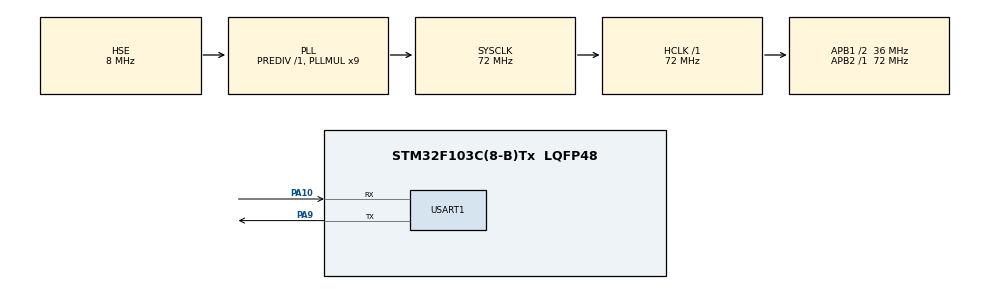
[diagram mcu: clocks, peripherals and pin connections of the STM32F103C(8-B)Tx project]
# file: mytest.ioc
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Dma.Request0=USART1_RX
Dma.Request1=USART1_TX
Dma.USART1_RX.0.Direction=DMA_PERIPH_TO_MEMORY
Dma.USART1_RX.0.Instance=DMA1_Channel5
Dma.USART1_RX.0.MemDataAlignment=DMA_MDATAALIGN_BYTE
Dma.USART1_RX.0.MemInc=DMA_MINC_ENABLE
Dma.USART1_RX.0.Mode=DMA_NORMAL
Dma.USART1_RX.0.PeriphDataAlignment=DMA_PDATAALIGN_BYTE
Dma.USART1_RX.0.PeriphInc=DMA_PINC_DISABLE
Dma.USART1_RX.0.Priority=DMA_PRIORITY_VERY_HIGH
Dma.USART1_TX.1.Direction=DMA_MEMORY_TO_PERIPH
Dma.USART1_TX.1.Instance=DMA1_Channel4
Dma.USART1_TX.1.MemDataAlignment=DMA_MDATAALIGN_BYTE
Dma.USART1_TX.1.MemInc=DMA_MINC_ENABLE
Dma.USART1_TX.1.Mode=DMA_NORMAL
Dma.USART1_TX.1.PeriphDataAlignment=DMA_PDATAALIGN_BYTE
Dma.USART1_TX.1.PeriphInc=DMA_PINC_DISABLE
Dma.USART1_TX.1.Priority=DMA_PRIORITY_VERY_HIGH
FREERTOS.Queues01=rxQueue,5,void *,0,Dynamic,NULL,NULL
FREERTOS.Tasks01=defaultTask,-2,128,StartDefaultTask,Default,NULL,Dynamic,NULL,NULL;main_task,0,128,StartTask02,Default,NULL,Dynamic,NULL,NULL;uartRx_task,2,256,uart_rx_entry,Default,NULL,Dynamic,NULL,NULL
FREERTOS.configTOTAL_HEAP_SIZE=4096
Mcu.Family=STM32F1
Mcu.Name=STM32F103C(8-B)Tx
Mcu.Package=LQFP48
NVIC.DMA1_Channel4_IRQn=true\:5\:0\:false\:false\:true\:true\:false\:true\:true
NVIC.DMA1_Channel5_IRQn=true\:5\:0\:true\:false\:true\:true\:false\:true\:true
NVIC.PriorityGroup=NVIC_PRIORITYGROUP_4
NVIC.TIM1_UP_IRQn=true\:0\:0\:false\:false\:true\:false\:false\:true\:true
NVIC.TimeBase=TIM1_UP_IRQn
NVIC.TimeBaseIP=TIM1
NVIC.USART1_IRQn=true\:5\:0\:true\:false\:true\:true\:true\:true\:true
PA10.Mode=Asynchronous
PA10.Signal=USART1_RX
PA13.Mode=Serial_Wire
PA13.Signal=SYS_JTMS-SWDIO
PA14.Mode=Serial_Wire
PA14.Signal=SYS_JTCK-SWCLK
PA9.Mode=Asynchronous
PA9.Signal=USART1_TX
PD0-OSC_IN.Mode=HSE-External-Oscillator
PD0-OSC_IN.Signal=RCC_OSC_IN
PD1-OSC_OUT.Mode=HSE-External-Oscillator
PD1-OSC_OUT.Signal=RCC_OSC_OUT
ProjectManager.HeapSize=0x200
ProjectManager.StackSize=0x400
ProjectManager.TargetToolchain=MDK-ARM V5.32
RCC.AHBFreq_Value=72000000
RCC.APB1CLKDivider=RCC_HCLK_DIV2
RCC.APB1Freq_Value=36000000
RCC.APB1TimFreq_Value=72000000
RCC.APB2Freq_Value=72000000
RCC.APB2TimFreq_Value=72000000
RCC.HCLKFreq_Value=72000000
RCC.PLLMUL=RCC_PLL_MUL9
RCC.PLLSourceVirtual=RCC_PLLSOURCE_HSE
RCC.SYSCLKFreq_VALUE=72000000
RCC.SYSCLKSource=RCC_SYSCLKSOURCE_PLLCLK
RCC.USBFreq_Value=72000000
USART1.VirtualMode=VM_ASYNC
VP_FREERTOS_VS_CMSIS_V1.Mode=CMSIS_V1
VP_SYS_VS_tim1.Mode=TIM1
board=custom

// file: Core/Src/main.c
/* USER CODE BEGIN Header */
/**
  ******************************************************************************
  * @file           : main.c
  * @brief          : Main program body
  ******************************************************************************
  * @attention
  *
  * Copyright (c) 2025 STMicroelectronics.
  * All rights reserved.
  *
  * This software is licensed under terms that can be found in the LICENSE file
  * in the root directory of this software component.
  * If no LICENSE file comes with this software, it is provided AS-IS.
  *
  ******************************************************************************
  */
/* USER CODE END Header */
#include "main.h"
#include "cmsis_os.h"
#include "dma.h"
#include "usart.h"
#include "gpio.h"

void SystemClock_Config(void);
void MX_FREERTOS_Init(void);

int main(void)
{

  /* MCU Configuration--------------------------------------------------------*/

  /* Reset of all peripherals, Initializes the Flash interface and the Systick. */
  HAL_Init();

  /* Configure the system clock */
  SystemClock_Config();

  /* Initialize all configured peripherals */
  MX_GPIO_Init();
  MX_DMA_Init();
  MX_USART1_UART_Init();

  /* Call init function for freertos objects (in freertos.c) */
  MX_FREERTOS_Init();

  /* Start scheduler */
  osKernelStart();

  /* We should never get here as control is now taken by the scheduler */
  /* Infinite loop */
  while (1)
  {

  }
}

void SystemClock_Config(void)
{
  RCC_OscInitTypeDef RCC_OscInitStruct = {0};
  RCC_ClkInitTypeDef RCC_ClkInitStruct = {0};

  /** Initializes the RCC Oscillators according to the specified parameters
  * in the RCC_OscInitTypeDef structure.
  */
  RCC_OscInitStruct.OscillatorType = RCC_OSCILLATORTYPE_HSE;
  RCC_OscInitStruct.HSEState = RCC_HSE_ON;
  RCC_OscInitStruct.HSEPredivValue = RCC_HSE_PREDIV_DIV1;
  RCC_OscInitStruct.HSIState = RCC_HSI_ON;
  RCC_OscInitStruct.PLL.PLLState = RCC_PLL_ON;
  RCC_OscInitStruct.PLL.PLLSource = RCC_PLLSOURCE_HSE;
  RCC_OscInitStruct.PLL.PLLMUL = RCC_PLL_MUL9;
  if (HAL_RCC_OscConfig(&RCC_OscInitStruct) != HAL_OK)
  {
    Error_Handler();
  }

  /** Initializes the CPU, AHB and APB buses clocks
  */
  RCC_ClkInitStruct.ClockType = RCC_CLOCKTYPE_HCLK|RCC_CLOCKTYPE_SYSCLK
                              |RCC_CLOCKTYPE_PCLK1|RCC_CLOCKTYPE_PCLK2;
  RCC_ClkInitStruct.SYSCLKSource = RCC_SYSCLKSOURCE_PLLCLK;
  RCC_ClkInitStruct.AHBCLKDivider = RCC_SYSCLK_DIV1;
  RCC_ClkInitStruct.APB1CLKDivider = RCC_HCLK_DIV2;
  RCC_ClkInitStruct.APB2CLKDivider = RCC_HCLK_DIV1;

  if (HAL_RCC_ClockConfig(&RCC_ClkInitStruct, FLASH_LATENCY_2) != HAL_OK)
  {
    Error_Handler();
  }
}

void HAL_TIM_PeriodElapsedCallback(TIM_HandleTypeDef *htim)
{
  if (htim->Instance == TIM1) {
    HAL_IncTick();
  }
}

void Error_Handler(void)
{
  __disable_irq();
  while (1)
  {
  }
}

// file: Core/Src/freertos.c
/* USER CODE BEGIN Header */
/**
  ******************************************************************************
  * File Name          : freertos.c
  * Description        : Code for freertos applications
  ******************************************************************************
  * @attention
  *
  * Copyright (c) 2025 STMicroelectronics.
  * All rights reserved.
  *
  * This software is licensed under terms that can be found in the LICENSE file
  * in the root directory of this software component.
  * If no LICENSE file comes with this software, it is provided AS-IS.
  *
  ******************************************************************************
  */
/* USER CODE END Header */

#include "FreeRTOS.h"
#include "task.h"
#include "main.h"
#include "cmsis_os.h"

/* USER CODE BEGIN Includes */
#include "dmaRingBuffer.h"
#include "rePrintf.h"
#include "shell_port.h"

/* USER CODE END Includes */

/* USER CODE BEGIN Variables */
extern UART_RX_TypeDef uart_rx_data_t[];
extern uint16_t uart_buff_ctrl ;
extern UART_HandleTypeDef huart1;

static char data     = 0;
static int  rcv_cnts = 0;

/* USER CODE END Variables */
osThreadId defaultTaskHandle;
osThreadId main_taskHandle;
osThreadId uartRx_taskHandle;
osMessageQId rxQueueHandle;

void StartDefaultTask(void const * argument);
void StartTask02(void const * argument);
void uart_rx_entry(void const * argument);

void MX_FREERTOS_Init(void); /* (MISRA C 2004 rule 8.1) */

/* GetIdleTaskMemory prototype (linked to static allocation support) */
void vApplicationGetIdleTaskMemory( StaticTask_t **ppxIdleTaskTCBBuffer, StackType_t **ppxIdleTaskStackBuffer, uint32_t *pulIdleTaskStackSize );

/* USER CODE BEGIN GET_IDLE_TASK_MEMORY */
static StaticTask_t xIdleTaskTCBBuffer;
static StackType_t xIdleStack[configMINIMAL_STACK_SIZE];

void vApplicationGetIdleTaskMemory( StaticTask_t **ppxIdleTaskTCBBuffer, StackType_t **ppxIdleTaskStackBuffer, uint32_t *pulIdleTaskStackSize )
{
  *ppxIdleTaskTCBBuffer = &xIdleTaskTCBBuffer;
  *ppxIdleTaskStackBuffer = &xIdleStack[0];
  *pulIdleTaskStackSize = configMINIMAL_STACK_SIZE;
  /* place for user code */
}
/* USER CODE END GET_IDLE_TASK_MEMORY */

void MX_FREERTOS_Init(void) {

  /* Create the queue(s) */
  /* definition and creation of rxQueue */
  osMessageQDef(rxQueue, 5, void *);
  rxQueueHandle = osMessageCreate(osMessageQ(rxQueue), NULL);

  /* Create the thread(s) */
  /* definition and creation of defaultTask */
  osThreadDef(defaultTask, StartDefaultTask, osPriorityLow, 0, 128);
  defaultTaskHandle = osThreadCreate(osThread(defaultTask), NULL);

  /* definition and creation of main_task */
  osThreadDef(main_task, StartTask02, osPriorityNormal, 0, 128);
  main_taskHandle = osThreadCreate(osThread(main_task), NULL);

  /* definition and creation of uartRx_task */
  osThreadDef(uartRx_task, uart_rx_entry, osPriorityHigh, 0, 256);
  uartRx_taskHandle = osThreadCreate(osThread(uartRx_task), NULL);

}

void StartDefaultTask(void const * argument)
{
  for(;;)
  {
    osDelay(1);
  }
}

void StartTask02(void const * argument)
{
  for(;;)
  {
    osDelay(1);
  }
}

void uart_rx_entry(void const * argument)
{
  /* USER CODE BEGIN uart_rx_entry */
   userShellInit();

   /*配置串口帧识别接收中断*/
   __HAL_UART_ENABLE_IT(&huart1 ,UART_IT_IDLE);
   HAL_UARTEx_ReceiveToIdle_DMA(&huart1 , uart_rx_data_t[uart_buff_ctrl].buffer,UART_BUFFER_SIZE);
   UART_RX_TypeDef *RecvUartData;

  /* Infinite loop */
  for(;;)
  {
    if(xQueueReceive(rxQueueHandle,&RecvUartData,portMAX_DELAY )== pdTRUE)
    {
		  #if 0
        //函数调试内容
        //队列中存入了数据
		  //将数据做了一个串口回显，当然你用作其它处理也可以
		  //HAL_UART_Transmit(&huart1,RecvUartData->buffer,RecvUartData->size,1000);
        #endif

        //此处需要对收到的字符串进行命令解析
        //此处需要按字节顺序对接收到的字符进行解析

       if( RecvUartData->size > 0 )
       { //有数据到达
          //接收计数器在使用前，清空为0
          rcv_cnts = 0;
          while( rcv_cnts < RecvUartData->size )
          {
             shellTask(&shell,(RecvUartData->buffer)[rcv_cnts]);
             rcv_cnts ++; //将索引增加一个字节
          }
       }
	 }
    //osDelay(1);
  }
  /* USER CODE END uart_rx_entry */
}
